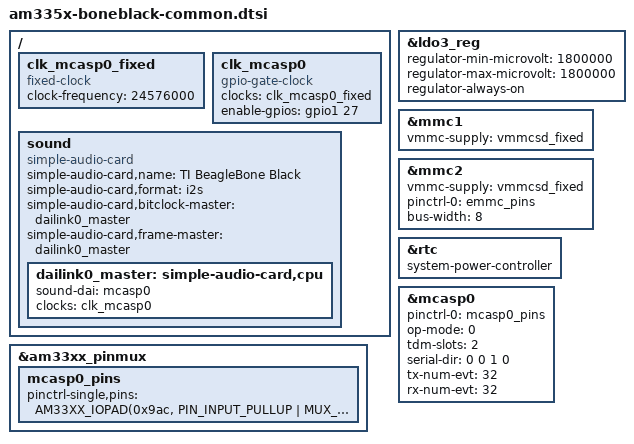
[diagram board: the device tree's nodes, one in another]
/*
 * Copyright (C) 2012 Texas Instruments Incorporated - http://www.ti.com/
 *
 * This program is free software; you can redistribute it and/or modify
 * it under the terms of the GNU General Public License version 2 as
 * published by the Free Software Foundation.
 */

#include <dt-bindings/display/tda998x.h>

&ldo3_reg {
	regulator-min-microvolt = <1800000>;
	regulator-max-microvolt = <1800000>;
	regulator-always-on;
};

&mmc1 {
	vmmc-supply = <&vmmcsd_fixed>;
};

&mmc2 {
	vmmc-supply = <&vmmcsd_fixed>;
	pinctrl-names = "default";
	pinctrl-0 = <&emmc_pins>;
	bus-width = <8>;
	status = "okay";
};

&am33xx_pinmux {
	mcasp0_pins: mcasp0_pins {
		pinctrl-single,pins = <
			AM33XX_IOPAD(0x9ac, PIN_INPUT_PULLUP | MUX_MODE0) /* mcasp0_ahcklx.mcasp0_ahclkx */
			AM33XX_IOPAD(0x99c, PIN_OUTPUT_PULLDOWN | MUX_MODE2) /* mcasp0_ahclkr.mcasp0_axr2*/
			AM33XX_IOPAD(0x994, PIN_OUTPUT_PULLUP | MUX_MODE0) /* mcasp0_fsx.mcasp0_fsx */
			AM33XX_IOPAD(0x990, PIN_OUTPUT_PULLDOWN | MUX_MODE0) /* mcasp0_aclkx.mcasp0_aclkx */
			AM33XX_IOPAD(0x86c, PIN_OUTPUT_PULLDOWN | MUX_MODE7) /* gpmc_a11.GPIO1_27 */
		>;
	};
};

&rtc {
	system-power-controller;
};

&mcasp0	{
	#sound-dai-cells = <0>;
	pinctrl-names = "default";
	pinctrl-0 = <&mcasp0_pins>;
	status = "okay";
	op-mode = <0>;	/* MCASP_IIS_MODE */
	tdm-slots = <2>;
	serial-dir = <	/* 0: INACTIVE, 1: TX, 2: RX */
			0 0 1 0
		>;
	tx-num-evt = <32>;
	rx-num-evt = <32>;
};

/ {
	clk_mcasp0_fixed: clk_mcasp0_fixed {
		#clock-cells = <0>;
		compatible = "fixed-clock";
		clock-frequency = <24576000>;
	};

	clk_mcasp0: clk_mcasp0 {
		#clock-cells = <0>;
		compatible = "gpio-gate-clock";
		clocks = <&clk_mcasp0_fixed>;
		enable-gpios = <&gpio1 27 0>; /* BeagleBone Black Clk enable on GPIO1_27 */
	};

	sound {
		compatible = "simple-audio-card";
		simple-audio-card,name = "TI BeagleBone Black";
		simple-audio-card,format = "i2s";
		simple-audio-card,bitclock-master = <&dailink0_master>;
		simple-audio-card,frame-master = <&dailink0_master>;

		dailink0_master: simple-audio-card,cpu {
			sound-dai = <&mcasp0>;
			clocks = <&clk_mcasp0>;
		};
	};
};
